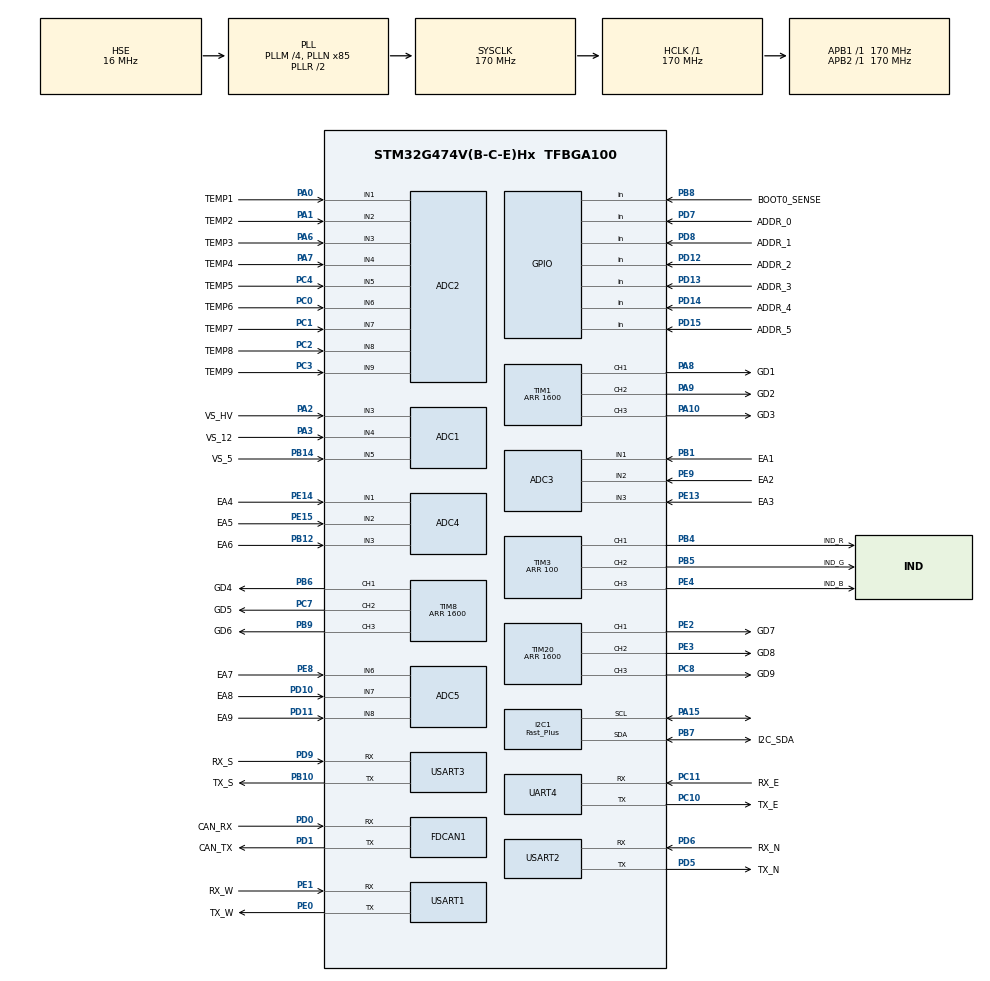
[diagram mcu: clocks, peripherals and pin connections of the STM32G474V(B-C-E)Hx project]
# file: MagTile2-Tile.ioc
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ADC1.Channel-1\#ChannelRegularConversion=ADC_CHANNEL_3
ADC1.Channel-2\#ChannelRegularConversion=ADC_CHANNEL_4
ADC1.Channel-3\#ChannelRegularConversion=ADC_CHANNEL_5
ADC1.Channel-4\#ChannelRegularConversion=ADC_CHANNEL_TEMPSENSOR_ADC1
ADC1.ClockPrescaler=ADC_CLOCK_ASYNC_DIV1
ADC1.ContinuousConvMode=ENABLE
ADC1.DMAContinuousRequests=ENABLE
ADC1.NbrOfConversion=4
ADC1.NbrOfConversionFlag=1
ADC1.OffsetNumber-1\#ChannelRegularConversion=ADC_OFFSET_NONE
ADC1.OffsetNumber-2\#ChannelRegularConversion=ADC_OFFSET_NONE
ADC1.OffsetNumber-3\#ChannelRegularConversion=ADC_OFFSET_NONE
ADC1.OffsetNumber-4\#ChannelRegularConversion=ADC_OFFSET_NONE
ADC1.OversamplingMode=ENABLE
ADC1.Rank-1\#ChannelRegularConversion=1
ADC1.Rank-2\#ChannelRegularConversion=2
ADC1.Rank-3\#ChannelRegularConversion=3
ADC1.Rank-4\#ChannelRegularConversion=4
ADC1.Ratio=ADC_OVERSAMPLING_RATIO_256
ADC1.RightBitShift=ADC_RIGHTBITSHIFT_4
ADC1.SamplingTime-1\#ChannelRegularConversion=ADC_SAMPLETIME_640CYCLES_5
ADC1.SamplingTime-2\#ChannelRegularConversion=ADC_SAMPLETIME_640CYCLES_5
ADC1.SamplingTime-3\#ChannelRegularConversion=ADC_SAMPLETIME_640CYCLES_5
ADC1.SamplingTime-4\#ChannelRegularConversion=ADC_SAMPLETIME_640CYCLES_5
ADC1.master=1
ADC2.Channel-0\#ChannelRegularConversion=ADC_CHANNEL_1
ADC2.Channel-1\#ChannelRegularConversion=ADC_CHANNEL_2
ADC2.Channel-2\#ChannelRegularConversion=ADC_CHANNEL_3
ADC2.Channel-3\#ChannelRegularConversion=ADC_CHANNEL_4
ADC2.Channel-4\#ChannelRegularConversion=ADC_CHANNEL_5
ADC2.Channel-5\#ChannelRegularConversion=ADC_CHANNEL_6
ADC2.Channel-6\#ChannelRegularConversion=ADC_CHANNEL_7
ADC2.Channel-7\#ChannelRegularConversion=ADC_CHANNEL_8
ADC2.Channel-8\#ChannelRegularConversion=ADC_CHANNEL_9
ADC2.ClockPrescaler=ADC_CLOCK_ASYNC_DIV1
ADC2.ContinuousConvMode=ENABLE
ADC2.DMAContinuousRequests=ENABLE
ADC2.NbrOfConversion=9
ADC2.NbrOfConversionFlag=1
ADC2.OffsetNumber-0\#ChannelRegularConversion=ADC_OFFSET_NONE
ADC2.OffsetNumber-1\#ChannelRegularConversion=ADC_OFFSET_NONE
ADC2.OffsetNumber-2\#ChannelRegularConversion=ADC_OFFSET_NONE
ADC2.OffsetNumber-3\#ChannelRegularConversion=ADC_OFFSET_NONE
ADC2.OffsetNumber-4\#ChannelRegularConversion=ADC_OFFSET_NONE
ADC2.OffsetNumber-5\#ChannelRegularConversion=ADC_OFFSET_NONE
ADC2.OffsetNumber-6\#ChannelRegularConversion=ADC_OFFSET_NONE
ADC2.OffsetNumber-7\#ChannelRegularConversion=ADC_OFFSET_NONE
ADC2.OffsetNumber-8\#ChannelRegularConversion=ADC_OFFSET_NONE
ADC2.OversamplingMode=ENABLE
ADC2.Rank-0\#ChannelRegularConversion=1
ADC2.Rank-1\#ChannelRegularConversion=2
ADC2.Rank-2\#ChannelRegularConversion=3
ADC2.Rank-3\#ChannelRegularConversion=4
ADC2.Rank-4\#ChannelRegularConversion=5
ADC2.Rank-5\#ChannelRegularConversion=6
ADC2.Rank-6\#ChannelRegularConversion=7
ADC2.Rank-7\#ChannelRegularConversion=8
ADC2.Rank-8\#ChannelRegularConversion=9
ADC2.Ratio=ADC_OVERSAMPLING_RATIO_16
ADC2.SamplingTime-0\#ChannelRegularConversion=ADC_SAMPLETIME_2CYCLES_5
ADC2.SamplingTime-1\#ChannelRegularConversion=ADC_SAMPLETIME_2CYCLES_5
ADC2.SamplingTime-2\#ChannelRegularConversion=ADC_SAMPLETIME_2CYCLES_5
ADC2.SamplingTime-3\#ChannelRegularConversion=ADC_SAMPLETIME_2CYCLES_5
ADC2.SamplingTime-4\#ChannelRegularConversion=ADC_SAMPLETIME_2CYCLES_5
ADC2.SamplingTime-5\#ChannelRegularConversion=ADC_SAMPLETIME_2CYCLES_5
ADC2.SamplingTime-6\#ChannelRegularConversion=ADC_SAMPLETIME_2CYCLES_5
ADC2.SamplingTime-7\#ChannelRegularConversion=ADC_SAMPLETIME_2CYCLES_5
ADC2.SamplingTime-8\#ChannelRegularConversion=ADC_SAMPLETIME_2CYCLES_5
ADC3.Channel-0\#ChannelRegularConversion=ADC_CHANNEL_1
ADC3.Channel-1\#ChannelRegularConversion=ADC_CHANNEL_2
ADC3.Channel-2\#ChannelRegularConversion=ADC_CHANNEL_3
ADC3.ClockPrescaler=ADC_CLOCK_ASYNC_DIV1
ADC3.ContinuousConvMode=ENABLE
ADC3.DMAContinuousRequests=ENABLE
ADC3.ExternalTrigConv=ADC_SOFTWARE_START
ADC3.NbrOfConversion=3
ADC3.NbrOfConversionFlag=1
ADC3.OffsetNumber-0\#ChannelRegularConversion=ADC_OFFSET_NONE
ADC3.OffsetNumber-1\#ChannelRegularConversion=ADC_OFFSET_NONE
ADC3.OffsetNumber-2\#ChannelRegularConversion=ADC_OFFSET_NONE
ADC3.Overrun=ADC_OVR_DATA_OVERWRITTEN
ADC3.OversamplingMode=ENABLE
ADC3.Rank-0\#ChannelRegularConversion=1
ADC3.Rank-1\#ChannelRegularConversion=2
ADC3.Rank-2\#ChannelRegularConversion=3
ADC3.Ratio=ADC_OVERSAMPLING_RATIO_16
ADC3.RightBitShift=ADC_RIGHTBITSHIFT_NONE
ADC3.SamplingTime-0\#ChannelRegularConversion=ADC_SAMPLETIME_47CYCLES_5
ADC3.SamplingTime-1\#ChannelRegularConversion=ADC_SAMPLETIME_47CYCLES_5
ADC3.SamplingTime-2\#ChannelRegularConversion=ADC_SAMPLETIME_47CYCLES_5
ADC3.master=1
ADC4.Channel-0\#ChannelRegularConversion=ADC_CHANNEL_1
ADC4.Channel-1\#ChannelRegularConversion=ADC_CHANNEL_2
ADC4.Channel-2\#ChannelRegularConversion=ADC_CHANNEL_3
ADC4.ClockPrescaler=ADC_CLOCK_ASYNC_DIV1
ADC4.ContinuousConvMode=ENABLE
ADC4.DMAContinuousRequests=ENABLE
ADC4.NbrOfConversion=3
ADC4.NbrOfConversionFlag=1
ADC4.OffsetNumber-0\#ChannelRegularConversion=ADC_OFFSET_NONE
ADC4.OffsetNumber-1\#ChannelRegularConversion=ADC_OFFSET_NONE
ADC4.OffsetNumber-2\#ChannelRegularConversion=ADC_OFFSET_NONE
ADC4.Overrun=ADC_OVR_DATA_OVERWRITTEN
ADC4.OversamplingMode=ENABLE
ADC4.Rank-0\#ChannelRegularConversion=1
ADC4.Rank-1\#ChannelRegularConversion=2
ADC4.Rank-2\#ChannelRegularConversion=3
ADC4.Ratio=ADC_OVERSAMPLING_RATIO_16
ADC4.RightBitShift=ADC_RIGHTBITSHIFT_NONE
ADC4.SamplingTime-0\#ChannelRegularConversion=ADC_SAMPLETIME_47CYCLES_5
ADC4.SamplingTime-1\#ChannelRegularConversion=ADC_SAMPLETIME_47CYCLES_5
ADC4.SamplingTime-2\#ChannelRegularConversion=ADC_SAMPLETIME_47CYCLES_5
ADC5.Channel-0\#ChannelRegularConversion=ADC_CHANNEL_6
ADC5.Channel-1\#ChannelRegularConversion=ADC_CHANNEL_7
ADC5.Channel-2\#ChannelRegularConversion=ADC_CHANNEL_8
ADC5.ClockPrescaler=ADC_CLOCK_ASYNC_DIV1
ADC5.ContinuousConvMode=ENABLE
ADC5.DMAContinuousRequests=ENABLE
ADC5.NbrOfConversion=3
ADC5.NbrOfConversionFlag=1
ADC5.OffsetNumber-0\#ChannelRegularConversion=ADC_OFFSET_NONE
ADC5.OffsetNumber-1\#ChannelRegularConversion=ADC_OFFSET_NONE
ADC5.OffsetNumber-2\#ChannelRegularConversion=ADC_OFFSET_NONE
ADC5.OversamplingMode=ENABLE
ADC5.Rank-0\#ChannelRegularConversion=1
ADC5.Rank-1\#ChannelRegularConversion=2
ADC5.Rank-2\#ChannelRegularConversion=3
ADC5.Ratio=ADC_OVERSAMPLING_RATIO_16
ADC5.RightBitShift=ADC_RIGHTBITSHIFT_NONE
ADC5.SamplingTime-0\#ChannelRegularConversion=ADC_SAMPLETIME_47CYCLES_5
ADC5.SamplingTime-1\#ChannelRegularConversion=ADC_SAMPLETIME_47CYCLES_5
ADC5.SamplingTime-2\#ChannelRegularConversion=ADC_SAMPLETIME_47CYCLES_5
Dma.ADC1.0.Direction=DMA_PERIPH_TO_MEMORY
Dma.ADC1.0.EventEnable=DISABLE
Dma.ADC1.0.Instance=DMA1_Channel1
Dma.ADC1.0.MemDataAlignment=DMA_MDATAALIGN_HALFWORD
Dma.ADC1.0.MemInc=DMA_MINC_ENABLE
Dma.ADC1.0.Mode=DMA_CIRCULAR
Dma.ADC1.0.PeriphDataAlignment=DMA_PDATAALIGN_HALFWORD
Dma.ADC1.0.PeriphInc=DMA_PINC_DISABLE
Dma.ADC1.0.Polarity=HAL_DMAMUX_REQ_GEN_RISING
Dma.ADC1.0.Priority=DMA_PRIORITY_MEDIUM
Dma.ADC1.0.RequestNumber=1
Dma.ADC1.0.SignalID=NONE
Dma.ADC1.0.SyncEnable=DISABLE
Dma.ADC1.0.SyncPolarity=HAL_DMAMUX_SYNC_NO_EVENT
Dma.ADC1.0.SyncRequestNumber=1
Dma.ADC1.0.SyncSignalID=NONE
Dma.ADC2.1.Direction=DMA_PERIPH_TO_MEMORY
Dma.ADC2.1.EventEnable=DISABLE
Dma.ADC2.1.Instance=DMA1_Channel2
Dma.ADC2.1.MemDataAlignment=DMA_MDATAALIGN_HALFWORD
Dma.ADC2.1.MemInc=DMA_MINC_ENABLE
Dma.ADC2.1.Mode=DMA_CIRCULAR
Dma.ADC2.1.PeriphDataAlignment=DMA_PDATAALIGN_HALFWORD
Dma.ADC2.1.PeriphInc=DMA_PINC_DISABLE
Dma.ADC2.1.Polarity=HAL_DMAMUX_REQ_GEN_RISING
Dma.ADC2.1.Priority=DMA_PRIORITY_LOW
Dma.ADC2.1.RequestNumber=1
Dma.ADC2.1.SignalID=NONE
Dma.ADC2.1.SyncEnable=DISABLE
Dma.ADC2.1.SyncPolarity=HAL_DMAMUX_SYNC_NO_EVENT
Dma.ADC2.1.SyncRequestNumber=1
Dma.ADC2.1.SyncSignalID=NONE
Dma.ADC3.2.Direction=DMA_PERIPH_TO_MEMORY
Dma.ADC3.2.EventEnable=DISABLE
Dma.ADC3.2.Instance=DMA1_Channel3
Dma.ADC3.2.MemDataAlignment=DMA_MDATAALIGN_HALFWORD
Dma.ADC3.2.MemInc=DMA_MINC_ENABLE
Dma.ADC3.2.Mode=DMA_CIRCULAR
Dma.ADC3.2.PeriphDataAlignment=DMA_PDATAALIGN_HALFWORD
Dma.ADC3.2.PeriphInc=DMA_PINC_DISABLE
Dma.ADC3.2.Polarity=HAL_DMAMUX_REQ_GEN_RISING
Dma.ADC3.2.Priority=DMA_PRIORITY_HIGH
Dma.ADC3.2.RequestNumber=1
Dma.ADC3.2.SignalID=NONE
Dma.ADC3.2.SyncEnable=DISABLE
Dma.ADC3.2.SyncPolarity=HAL_DMAMUX_SYNC_NO_EVENT
Dma.ADC3.2.SyncRequestNumber=1
Dma.ADC3.2.SyncSignalID=NONE
Dma.ADC4.3.Direction=DMA_PERIPH_TO_MEMORY
Dma.ADC4.3.EventEnable=DISABLE
Dma.ADC4.3.Instance=DMA1_Channel4
Dma.ADC4.3.MemDataAlignment=DMA_MDATAALIGN_HALFWORD
Dma.ADC4.3.MemInc=DMA_MINC_ENABLE
Dma.ADC4.3.Mode=DMA_CIRCULAR
Dma.ADC4.3.PeriphDataAlignment=DMA_PDATAALIGN_HALFWORD
Dma.ADC4.3.PeriphInc=DMA_PINC_DISABLE
Dma.ADC4.3.Polarity=HAL_DMAMUX_REQ_GEN_RISING
Dma.ADC4.3.Priority=DMA_PRIORITY_HIGH
Dma.ADC4.3.RequestNumber=1
Dma.ADC4.3.SignalID=NONE
Dma.ADC4.3.SyncEnable=DISABLE
Dma.ADC4.3.SyncPolarity=HAL_DMAMUX_SYNC_NO_EVENT
Dma.ADC4.3.SyncRequestNumber=1
Dma.ADC4.3.SyncSignalID=NONE
Dma.ADC5.4.Direction=DMA_PERIPH_TO_MEMORY
Dma.ADC5.4.EventEnable=DISABLE
Dma.ADC5.4.Instance=DMA1_Channel5
Dma.ADC5.4.MemDataAlignment=DMA_MDATAALIGN_HALFWORD
Dma.ADC5.4.MemInc=DMA_MINC_ENABLE
Dma.ADC5.4.Mode=DMA_CIRCULAR
Dma.ADC5.4.PeriphDataAlignment=DMA_PDATAALIGN_HALFWORD
Dma.ADC5.4.PeriphInc=DMA_PINC_DISABLE
Dma.ADC5.4.Polarity=HAL_DMAMUX_REQ_GEN_RISING
Dma.ADC5.4.Priority=DMA_PRIORITY_HIGH
Dma.ADC5.4.RequestNumber=1
Dma.ADC5.4.SignalID=NONE
Dma.ADC5.4.SyncEnable=DISABLE
Dma.ADC5.4.SyncPolarity=HAL_DMAMUX_SYNC_NO_EVENT
Dma.ADC5.4.SyncRequestNumber=1
Dma.ADC5.4.SyncSignalID=NONE
Dma.Request0=ADC1
Dma.Request1=ADC2
Dma.Request2=ADC3
Dma.Request3=ADC4
Dma.Request4=ADC5
FDCAN1.AutoRetransmission=ENABLE
FDCAN1.CalculateBaudRateNominal=500000
FDCAN1.CalculateTimeBitNominal=2000
FDCAN1.CalculateTimeQuantumNominal=100.0
FDCAN1.ClockDivider=FDCAN_CLOCK_DIV1
FDCAN1.DataPrescaler=6
FDCAN1.DataSyncJumpWidth=4
FDCAN1.DataTimeSeg1=11
FDCAN1.DataTimeSeg2=5
FDCAN1.FrameFormat=FDCAN_FRAME_FD_BRS
FDCAN1.NominalPrescaler=17
FDCAN1.NominalSyncJumpWidth=4
FDCAN1.NominalTimeSeg1=13
FDCAN1.NominalTimeSeg2=6
FDCAN1.TransmitPause=ENABLE
I2C1.I2C_Fall_Time=0
I2C1.I2C_Rise_Time=0
I2C1.I2C_Speed_Mode=I2C_Fast_Plus
I2C1.OwnAddress=0x01
I2C1.Timing=0x00802172
Mcu.Family=STM32G4
Mcu.Name=STM32G474V(B-C-E)Hx
Mcu.Package=TFBGA100
NVIC.DMA1_Channel1_IRQn=true\:1\:0\:true\:false\:true\:false\:true\:true
NVIC.DMA1_Channel2_IRQn=true\:3\:0\:true\:false\:true\:false\:true\:true
NVIC.DMA1_Channel3_IRQn=true\:0\:0\:true\:false\:true\:false\:true\:true
NVIC.DMA1_Channel4_IRQn=true\:0\:0\:true\:false\:true\:false\:true\:true
NVIC.DMA1_Channel5_IRQn=true\:0\:0\:true\:false\:true\:false\:true\:true
NVIC.FDCAN1_IT0_IRQn=true\:2\:0\:true\:false\:true\:true\:true\:true
NVIC.FDCAN1_IT1_IRQn=true\:2\:0\:true\:false\:true\:true\:true\:true
NVIC.PriorityGroup=NVIC_PRIORITYGROUP_4
NVIC.UART4_IRQn=true\:5\:0\:true\:false\:true\:true\:true\:true
NVIC.USART1_IRQn=true\:5\:0\:true\:false\:true\:true\:true\:true
NVIC.USART2_IRQn=true\:5\:0\:true\:false\:true\:true\:true\:true
NVIC.USART3_IRQn=true\:5\:0\:true\:false\:true\:true\:true\:true
PA0.GPIO_Label=TEMP1
PA0.Mode=IN1-Single-Ended
PA0.Signal=ADC2_IN1
PA1.GPIO_Label=TEMP2
PA1.Mode=IN2-Single-Ended
PA1.Signal=ADC2_IN2
PA10.GPIO_Label=GD3
PA10.Signal=S_TIM1_CH3
PA13.GPIO_Label=SWDIO
PA13.Mode=Trace_Asynchronous_SW
PA13.Signal=SYS_JTMS-SWDIO
PA14.GPIO_Label=SWCLK
PA14.Mode=Trace_Asynchronous_SW
PA14.Signal=SYS_JTCK-SWCLK
PA15.GPIO_Pu=GPIO_NOPULL
PA15.GPIO_Speed=GPIO_SPEED_FREQ_HIGH
PA15.Mode=I2C
PA15.Signal=I2C1_SCL
PA2.GPIO_Label=VS_HV
PA2.Mode=IN3-Single-Ended
PA2.Signal=ADC1_IN3
PA3.GPIO_Label=VS_12
PA3.Mode=IN4-Single-Ended
PA3.Signal=ADC1_IN4
PA6.GPIO_Label=TEMP3
PA6.Mode=IN3-Single-Ended
PA6.Signal=ADC2_IN3
PA7.GPIO_Label=TEMP4
PA7.Mode=IN4-Single-Ended
PA7.Signal=ADC2_IN4
PA8.GPIO_Label=GD1
PA8.Signal=S_TIM1_CH1
PA9.GPIO_Label=GD2
PA9.Signal=S_TIM1_CH2
PB1.GPIO_Label=EA1
PB1.Mode=IN1-Single-Ended
PB1.Signal=ADC3_IN1
PB10.GPIO_Label=TX_S
PB10.Mode=Asynchronous
PB10.Signal=USART3_TX
PB12.GPIO_Label=EA6
PB12.Mode=IN3-Single-Ended
PB12.Signal=ADC4_IN3
PB14.GPIO_Label=VS_5
PB14.Mode=IN5-Single-Ended
PB14.Signal=ADC1_IN5
PB3.GPIO_Label=SWO
PB3.Mode=Trace_Asynchronous_SW
PB3.Signal=SYS_JTDO-SWO
PB4.GPIO_Label=IND_R
PB4.Signal=S_TIM3_CH1
PB5.GPIO_Label=IND_G
PB5.Signal=S_TIM3_CH2
PB6.GPIO_Label=GD4
PB6.Signal=S_TIM8_CH1
PB7.GPIO_FM7=__NULL
PB7.GPIO_Label=I2C_SDA
PB7.GPIO_Pu=GPIO_NOPULL
PB7.GPIO_Speed=GPIO_SPEED_FREQ_HIGH
PB7.Mode=I2C
PB7.Signal=I2C1_SDA
PB8-BOOT0.GPIO_Label=BOOT0_SENSE
PB8-BOOT0.Signal=GPIO_Input
PB9.GPIO_Label=GD6
PB9.Signal=S_TIM8_CH3
PC0.GPIO_Label=TEMP6
PC0.Mode=IN6-Single-Ended
PC0.Signal=ADC2_IN6
PC1.GPIO_Label=TEMP7
PC1.Mode=IN7-Single-Ended
PC1.Signal=ADC2_IN7
PC10.GPIO_Label=TX_E
PC10.Mode=Asynchronous
PC10.Signal=UART4_TX
PC11.GPIO_Label=RX_E
PC11.Mode=Asynchronous
PC11.Signal=UART4_RX
PC2.GPIO_Label=TEMP8
PC2.Mode=IN8-Single-Ended
PC2.Signal=ADC2_IN8
PC3.GPIO_Label=TEMP9
PC3.Mode=IN9-Single-Ended
PC3.Signal=ADC2_IN9
PC4.GPIO_Label=TEMP5
PC4.Mode=IN5-Single-Ended
PC4.Signal=ADC2_IN5
PC7.GPIO_Label=GD5
PC7.Signal=S_TIM8_CH2
PC8.GPIO_Label=GD9
PC8.Signal=S_TIM20_CH3
PD0.GPIO_Label=CAN_RX
PD0.Mode=FDCAN_Activate
PD0.Signal=FDCAN1_RX
PD1.GPIO_Label=CAN_TX
PD1.Mode=FDCAN_Activate
PD1.Signal=FDCAN1_TX
PD10.GPIO_Label=EA8
PD10.Mode=IN7-Single-Ended
PD10.Signal=ADC5_IN7
PD11.GPIO_Label=EA9
PD11.Mode=IN8-Single-Ended
PD11.Signal=ADC5_IN8
PD12.GPIO_Label=ADDR_2
PD12.GPIO_PuPd=GPIO_PULLUP
PD12.Signal=GPIO_Input
PD13.GPIO_Label=ADDR_3
PD13.GPIO_PuPd=GPIO_PULLUP
PD13.Signal=GPIO_Input
PD14.GPIO_Label=ADDR_4
PD14.GPIO_PuPd=GPIO_PULLUP
PD14.Signal=GPIO_Input
PD15.GPIO_Label=ADDR_5
PD15.GPIO_PuPd=GPIO_PULLUP
PD15.Signal=GPIO_Input
PD5.GPIO_Label=TX_N
PD5.Mode=Asynchronous
PD5.Signal=USART2_TX
PD6.GPIO_Label=RX_N
PD6.Mode=Asynchronous
PD6.Signal=USART2_RX
PD7.GPIO_Label=ADDR_0
PD7.GPIO_PuPd=GPIO_PULLUP
PD7.Signal=GPIO_Input
PD8.GPIO_Label=ADDR_1
PD8.GPIO_PuPd=GPIO_PULLUP
PD8.Signal=GPIO_Input
PD9.GPIO_Label=RX_S
PD9.Mode=Asynchronous
PD9.Signal=USART3_RX
PE0.GPIO_Label=TX_W
PE0.Mode=Asynchronous
PE0.Signal=USART1_TX
PE1.GPIO_Label=RX_W
PE1.Mode=Asynchronous
PE1.Signal=USART1_RX
PE13.GPIO_Label=EA3
PE13.Mode=IN3-Single-Ended
PE13.Signal=ADC3_IN3
PE14.GPIO_Label=EA4
PE14.Mode=IN1-Single-Ended
PE14.Signal=ADC4_IN1
PE15.GPIO_Label=EA5
PE15.Mode=IN2-Single-Ended
PE15.Signal=ADC4_IN2
PE2.GPIO_Label=GD7
PE2.Signal=S_TIM20_CH1
PE3.GPIO_Label=GD8
PE3.Signal=S_TIM20_CH2
PE4.GPIO_Label=IND_B
PE4.Signal=S_TIM3_CH3
PE8.GPIO_Label=EA7
PE8.Mode=IN6-Single-Ended
PE8.Signal=ADC5_IN6
PE9.GPIO_Label=EA2
PE9.Mode=IN2-Single-Ended
PE9.Signal=ADC3_IN2
PF0-OSC_IN.GPIO_Label=HSE_IN
PF0-OSC_IN.Mode=HSE-External-Oscillator
PF0-OSC_IN.Signal=RCC_OSC_IN
PF1-OSC_OUT.GPIO_Label=HSE_OUT
PF1-OSC_OUT.Mode=HSE-External-Oscillator
PF1-OSC_OUT.Signal=RCC_OSC_OUT
ProjectManager.HeapSize=0x200
ProjectManager.StackSize=0x400
ProjectManager.TargetToolchain=STM32CubeIDE
RCC.ADC12CLockSelection=RCC_ADC12CLKSOURCE_PLL
RCC.ADC12Freq_Value=48571428.571428575
RCC.ADC345CLockSelection=RCC_ADC345CLKSOURCE_PLL
RCC.ADC345Freq_Value=48571428.571428575
RCC.AHBFreq_Value=170000000
RCC.APB1Freq_Value=170000000
RCC.APB1TimFreq_Value=170000000
RCC.APB2Freq_Value=170000000
RCC.APB2TimFreq_Value=170000000
RCC.CortexFreq_Value=170000000
RCC.EXTERNAL_CLOCK_VALUE=12288000
RCC.FDCANCLockSelection=RCC_FDCANCLKSOURCE_PLL
RCC.HCLKFreq_Value=170000000
RCC.HSE_VALUE=16000000
RCC.HSI48_VALUE=48000000
RCC.HSI_VALUE=16000000
RCC.LSE_VALUE=32768
RCC.PLLM=RCC_PLLM_DIV4
RCC.PLLN=85
RCC.PLLP=RCC_PLLP_DIV7
RCC.PLLSourceVirtual=RCC_PLLSOURCE_HSE
RCC.SYSCLKFreq_VALUE=170000000
RCC.SYSCLKSource=RCC_SYSCLKSOURCE_PLLCLK
RCC.USBFreq_Value=170000000
RCC.VCOOutputFreq_Value=340000000
SH.S_TIM1_CH1.0=TIM1_CH1,PWM Generation1 CH1
SH.S_TIM1_CH2.0=TIM1_CH2,PWM Generation2 CH2
SH.S_TIM1_CH3.0=TIM1_CH3,PWM Generation3 CH3
SH.S_TIM20_CH1.0=TIM20_CH1,PWM Generation1 CH1
SH.S_TIM20_CH2.0=TIM20_CH2,PWM Generation2 CH2
SH.S_TIM20_CH3.0=TIM20_CH3,PWM Generation3 CH3
SH.S_TIM3_CH1.0=TIM3_CH1,PWM Generation1 CH1
SH.S_TIM3_CH2.0=TIM3_CH2,PWM Generation2 CH2
SH.S_TIM3_CH3.0=TIM3_CH3,PWM Generation3 CH3
SH.S_TIM8_CH1.0=TIM8_CH1,PWM Generation1 CH1
SH.S_TIM8_CH2.0=TIM8_CH2,PWM Generation2 CH2
SH.S_TIM8_CH3.0=TIM8_CH3,PWM Generation3 CH3
TIM1.Channel-PWM\ Generation1\ CH1=TIM_CHANNEL_1
TIM1.Channel-PWM\ Generation2\ CH2=TIM_CHANNEL_2
TIM1.Channel-PWM\ Generation3\ CH3=TIM_CHANNEL_3
TIM1.OCFastMode_PWM-PWM\ Generation1\ CH1=TIM_OCFAST_ENABLE
TIM1.OCFastMode_PWM-PWM\ Generation2\ CH2=TIM_OCFAST_ENABLE
TIM1.OCFastMode_PWM-PWM\ Generation3\ CH3=TIM_OCFAST_ENABLE
TIM1.PeriodNoDither=1600
TIM2.Dithering=Disable
TIM2.Prescaler=16999
TIM20.Channel-PWM\ Generation1\ CH1=TIM_CHANNEL_1
TIM20.Channel-PWM\ Generation2\ CH2=TIM_CHANNEL_2
TIM20.Channel-PWM\ Generation3\ CH3=TIM_CHANNEL_3
TIM20.PeriodNoDither=1600
TIM3.Channel-PWM\ Generation1\ CH1=TIM_CHANNEL_1
TIM3.Channel-PWM\ Generation2\ CH2=TIM_CHANNEL_2
TIM3.Channel-PWM\ Generation3\ CH3=TIM_CHANNEL_3
TIM3.OCPolarity_1=TIM_OCPOLARITY_LOW
TIM3.OCPolarity_2=TIM_OCPOLARITY_LOW
TIM3.OCPolarity_3=TIM_OCPOLARITY_LOW
TIM3.PeriodNoDither=100
TIM3.PulseNoDither_1=50
TIM3.PulseNoDither_2=50
TIM6.PeriodNoDither=100
TIM6.Prescaler=168
TIM6.TIM_MasterOutputTrigger=TIM_TRGO_UPDATE
TIM8.Channel-PWM\ Generation1\ CH1=TIM_CHANNEL_1
TIM8.Channel-PWM\ Generation2\ CH2=TIM_CHANNEL_2
TIM8.Channel-PWM\ Generation3\ CH3=TIM_CHANNEL_3
TIM8.PeriodNoDither=1600
USART1.VirtualMode-Asynchronous=VM_ASYNC
USART2.VirtualMode-Asynchronous=VM_ASYNC
USART3.VirtualMode-Asynchronous=VM_ASYNC
VP_ADC1_TempSens_Input.Mode=IN-TempSens
VP_SYS_VS_DBSignals.Mode=DisableDeadBatterySignals
VP_TIM1_VS_ClockSourceINT.Mode=Internal
VP_TIM20_VS_ClockSourceINT.Mode=Internal
VP_TIM2_VS_ClockSourceINT.Mode=Internal
VP_TIM3_VS_ClockSourceINT.Mode=Internal
VP_TIM6_VS_ClockSourceINT.Mode=Enable_Timer
VP_TIM8_VS_ClockSourceINT.Mode=Internal
board=custom

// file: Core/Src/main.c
/* USER CODE BEGIN Header */
/**
 ******************************************************************************
 * @file           : main.c
 * @brief          : Main program body
 ******************************************************************************
 * @attention
 *
 * Copyright (c) 2025 STMicroelectronics.
 * All rights reserved.
 *
 * This software is licensed under terms that can be found in the LICENSE file
 * in the root directory of this software component.
 * If no LICENSE file comes with this software, it is provided AS-IS.
 *
 ******************************************************************************
 */
/* USER CODE END Header */
#include "main.h"

/* USER CODE BEGIN Includes */

#include "i2c_slave.h"
#include "can.h"
#include "adc.h"
#include "telemetry.h"
#include "graph_uart.h"
#include "safety_config.h"

/* USER CODE END Includes */

/* USER CODE BEGIN PD */

#define I2C_BUFFER_SIZE 2
#define CAN_BLINK_FREQ 200 // ms
#define CAN_BLINK_TIME 100 // ms
#define ID_BLINK_FREQ 300 // ms
#define ID_BLINK_TIME 100 // ms

/* USER CODE END PD */

ADC_HandleTypeDef hadc1;
ADC_HandleTypeDef hadc2;
ADC_HandleTypeDef hadc3;
ADC_HandleTypeDef hadc4;
ADC_HandleTypeDef hadc5;
DMA_HandleTypeDef hdma_adc1;
DMA_HandleTypeDef hdma_adc2;
DMA_HandleTypeDef hdma_adc3;
DMA_HandleTypeDef hdma_adc4;
DMA_HandleTypeDef hdma_adc5;

FDCAN_HandleTypeDef hfdcan1;

I2C_HandleTypeDef hi2c1;

TIM_HandleTypeDef htim1;
TIM_HandleTypeDef htim2;
TIM_HandleTypeDef htim3;
TIM_HandleTypeDef htim6;
TIM_HandleTypeDef htim8;
TIM_HandleTypeDef htim20;

UART_HandleTypeDef huart4;
UART_HandleTypeDef huart1;
UART_HandleTypeDef huart2;
UART_HandleTypeDef huart3;

/* USER CODE BEGIN PV */

uint16_t build_number = 24;

unsigned int hardware_tick = 0; // hardware tick counter

// global variables for all digital inputs
uint8_t BOOT0_SENSE;

uint8_t my_address = 0x00;

MT2_Slave_Status slave_status;
MT2_Slave_Faults slave_faults;
MT2_Global_State global_state;
MT2_Slave_Settings slave_settings;

uint8_t adj_west_addr;
uint8_t adj_north_addr;
uint8_t adj_east_addr;
uint8_t adj_south_addr;

volatile float coil_current_1 = 0;

// PWM outputs
uint16_t coil_pwm_ccr_1 = 0;

FDCAN_RxHeaderTypeDef rxHeader;
uint8_t rxData[8];
uint8_t i2c_blink = 0;
uint8_t can_blink = 0;

int32_t can_latency = 0; // time since last CAN message received
uint8_t can_timeout = 0; // flag for CAN timeout

// I2C RX buffer
uint8_t i2cRxBuffer[I2C_BUFFER_SIZE];
uint8_t i2cRxIndex = 0;
uint8_t i2cDataReady = 0;

uint32_t main_loop_counter = 0; // main loop counter for debugging
volatile uint32_t adc3_loop_counter = 0; // adc1 loop counter for debugging
volatile uint32_t adc4_loop_counter = 0; // adc2 loop counter for debugging
volatile uint32_t adc5_loop_counter = 0; // adc3 loop counter for debugging
uint32_t main_loop_freq = 0; // main loop frequency in Hz
uint32_t adc3_loop_freq = 0; // adc1 loop frequency in Hz
uint32_t adc4_loop_freq = 0; // adc2 loop frequency in Hz
uint32_t adc5_loop_freq = 0; // adc3 loop frequency in Hz

/* USER CODE END PV */

void SystemClock_Config(void);
static void MX_GPIO_Init(void);
static void MX_DMA_Init(void);
static void MX_ADC1_Init(void);
static void MX_ADC2_Init(void);
static void MX_ADC3_Init(void);
static void MX_ADC4_Init(void);
static void MX_ADC5_Init(void);
static void MX_TIM1_Init(void);
static void MX_TIM8_Init(void);
static void MX_TIM20_Init(void);
static void MX_FDCAN1_Init(void);
static void MX_I2C1_Init(void);
static void MX_TIM3_Init(void);
static void MX_UART4_Init(void);
static void MX_USART1_UART_Init(void);
static void MX_USART2_UART_Init(void);
static void MX_USART3_UART_Init(void);
static void MX_TIM6_Init(void);
static void MX_TIM2_Init(void);

/* USER CODE BEGIN 0 */

#define _set_rgb(r, g, b) \
	__HAL_TIM_SET_COMPARE(&htim3, TIM_CHANNEL_1, (g)); \
	__HAL_TIM_SET_COMPARE(&htim3, TIM_CHANNEL_2, (r)); \
	__HAL_TIM_SET_COMPARE(&htim3, TIM_CHANNEL_3, (b)); \

#define LED_BRIGHTNESS_DIVIDE 2
void set_rgb(uint8_t r, uint8_t g, uint8_t b) {
	_set_rgb(r/LED_BRIGHTNESS_DIVIDE, g/LED_BRIGHTNESS_DIVIDE, b/LED_BRIGHTNESS_DIVIDE);
}

/* USER CODE END 0 */

int main(void)
{

  /* MCU Configuration--------------------------------------------------------*/

  /* Reset of all peripherals, Initializes the Flash interface and the Systick. */
  HAL_Init();

  /* Configure the system clock */
  SystemClock_Config();

  /* Initialize all configured peripherals */
  MX_GPIO_Init();
  MX_DMA_Init();
  MX_ADC1_Init();
  MX_ADC2_Init();
  MX_ADC3_Init();
  MX_ADC4_Init();
  MX_ADC5_Init();
  MX_TIM1_Init();
  MX_TIM8_Init();
  MX_TIM20_Init();
  MX_FDCAN1_Init();
  MX_I2C1_Init();
  MX_TIM3_Init();
  MX_UART4_Init();
  MX_USART1_UART_Init();
  MX_USART2_UART_Init();
  MX_USART3_UART_Init();
  MX_TIM6_Init();
  MX_TIM2_Init();
  /* USER CODE BEGIN 2 */

  // start hardware tick timer
  HAL_TIM_Base_Start(&htim2);

	// 1: green; 2: red; 3: blue
	// set LED to red
//	set_rgb(100, 0, 0);

	// turn on LED pwm
	HAL_TIM_PWM_Start(&htim3, TIM_CHANNEL_1);
	HAL_TIM_PWM_Start(&htim3, TIM_CHANNEL_2);
	HAL_TIM_PWM_Start(&htim3, TIM_CHANNEL_3);

//	HAL_Delay(1000);

	uint8_t new_addr_switches = 0;
	new_addr_switches |= !HAL_GPIO_ReadPin(ADDR_0_GPIO_Port, ADDR_0_Pin) << 5;
	new_addr_switches |= !HAL_GPIO_ReadPin(ADDR_1_GPIO_Port, ADDR_1_Pin) << 4;
	new_addr_switches |= !HAL_GPIO_ReadPin(ADDR_2_GPIO_Port, ADDR_2_Pin) << 3;
	new_addr_switches |= !HAL_GPIO_ReadPin(ADDR_3_GPIO_Port, ADDR_3_Pin) << 2;
	new_addr_switches |= !HAL_GPIO_ReadPin(ADDR_4_GPIO_Port, ADDR_4_Pin) << 1;
	new_addr_switches |= !HAL_GPIO_ReadPin(ADDR_5_GPIO_Port, ADDR_5_Pin) << 0;
	my_address = new_addr_switches + 1;
	hi2c1.Init.OwnAddress1 = my_address << 1;
	HAL_I2C_Init(&hi2c1);

	// start the ADCs
//	HAL_ADC_Start_IT(&hadc3);
	ADC_Init(&hadc1, &hadc2, &hadc3, &hadc4, &hadc5);

	// start the timer
	HAL_TIM_Base_Start(&htim6);

	// start the gate drive PWM timers
	HAL_TIM_PWM_Start(&htim1, TIM_CHANNEL_1);
	HAL_TIM_PWM_Start(&htim1, TIM_CHANNEL_2);
	HAL_TIM_PWM_Start(&htim1, TIM_CHANNEL_3);
	HAL_TIM_PWM_Start(&htim8, TIM_CHANNEL_1);
	HAL_TIM_PWM_Start(&htim8, TIM_CHANNEL_2);
	HAL_TIM_PWM_Start(&htim8, TIM_CHANNEL_3);
	HAL_TIM_PWM_Start(&htim20, TIM_CHANNEL_1);
	HAL_TIM_PWM_Start(&htim20, TIM_CHANNEL_2);
	HAL_TIM_PWM_Start(&htim20, TIM_CHANNEL_3);

	// start CAN
	CAN_Init(&hfdcan1);

	slave_status.flags.alive = 1;

	Telemetry_Init();

	I2C_Slave_Init(&hi2c1);

	GraphUART_Init(&huart2, &huart4, &huart3, &huart1);

	CoreDebug->DEMCR |= CoreDebug_DEMCR_TRCENA_Msk; // Enable trace
	ITM->LAR  = 0xC5ACCE55;                         // Unlock ITM
	ITM->TCR  = ITM_TCR_ITMENA_Msk |                // Enable ITM
				ITM_TCR_SYNCENA_Msk |               // Enable sync packets (optional)
				ITM_TCR_TSENA_Msk;                  // Enable timestamping (optional)
	ITM->TER  = 0xFFFFFFFF;                         // Enable all stimulus ports

	// set LED to yellow
//	set_rgb(100, 100, 0);

	uint32_t graph_uart_start = HAL_GetTick();

	uint32_t can_blink_start = HAL_GetTick();
	uint32_t id_blink_start = HAL_GetTick();
	uint32_t loop_diagnostics_start = HAL_GetTick();

	uint8_t led_off = 0; // flag to indicate if led is off
	uint8_t led_id_mode = 0; // flag to indicate if in id mode

  /* USER CODE END 2 */

  /* Infinite loop */
	while (1) {

    /* USER CODE BEGIN 3 */

		// set hardware tick
		hardware_tick = __HAL_TIM_GET_COUNTER(&htim2) / 10;

		// read digital inputs
		BOOT0_SENSE = HAL_GPIO_ReadPin(BOOT0_SENSE_GPIO_Port, BOOT0_SENSE_Pin);

		// set timer output
		__HAL_TIM_SET_COMPARE(&htim1, TIM_CHANNEL_1, coil_pwm_ccr[0]);
		__HAL_TIM_SET_COMPARE(&htim1, TIM_CHANNEL_2, coil_pwm_ccr[1]);
		__HAL_TIM_SET_COMPARE(&htim1, TIM_CHANNEL_3, coil_pwm_ccr[2]);
		__HAL_TIM_SET_COMPARE(&htim8, TIM_CHANNEL_1, coil_pwm_ccr[3]);
		__HAL_TIM_SET_COMPARE(&htim8, TIM_CHANNEL_2, coil_pwm_ccr[4]);
		__HAL_TIM_SET_COMPARE(&htim8, TIM_CHANNEL_3, coil_pwm_ccr[5]);
		__HAL_TIM_SET_COMPARE(&htim20, TIM_CHANNEL_1, coil_pwm_ccr[6]);
		__HAL_TIM_SET_COMPARE(&htim20, TIM_CHANNEL_2, coil_pwm_ccr[7]);
		__HAL_TIM_SET_COMPARE(&htim20, TIM_CHANNEL_3, coil_pwm_ccr[8]);

		// STATE MACHINE START

		// check global state parameters
		if (global_state.flags.global_fault_clear || slave_settings.flags.local_fault_clear) {
			slave_status.flags.shutdown_from_fault = 0;
		}

		// check if any coils are on
		for (int i = 0; i < 9; i++) {
			if (coil_setpoint[i] > 0) {
				slave_status.flags.coils_nonzero = 1;
				break;
			} else {
				slave_status.flags.coils_nonzero = 0;
			}
		}

		// CAN-related state
		if (!slave_status.flags.arm_active && !slave_status.flags.shutdown_from_fault) {
			slave_faults.flags.communication_fault = 0;
		}
		can_latency = HAL_GetTick() - can_last_heard_from_master;
		if (can_latency > CAN_TIMEOUT) {
			can_timeout = 1;
			global_state.flags.global_led_disable = 0;
			slave_faults.flags.communication_fault = 1;
		}
		else {
			can_timeout = 0;
		}

		// check for faults and disarm
		if (slave_status.flags.arm_active && slave_faults.byte) {
			slave_status.flags.shutdown_from_fault = 1;
			slave_status.flags.arm_active = 0;
		}

		if (slave_faults.byte)
			slave_status.flags.arm_ready = 0;
		else
			slave_status.flags.arm_ready = 1;

		// now finally if there are no faults and the global arm request is on
		if (global_state.flags.global_arm && !slave_faults.byte) {
			slave_status.flags.arm_active = 1;
		} else {
			slave_status.flags.arm_active = 0;
		}

		// POST STATE MACHINE

	    // turn can led off for CAN_BLINK_TIME every CAN_BLINK_FREQ ms
		if (HAL_GetTick() - can_blink_start > CAN_BLINK_FREQ) {
			can_blink_start = HAL_GetTick();
			if (can_timeout) led_off = 1;
		}
		if (HAL_GetTick() - can_blink_start > CAN_BLINK_TIME) {
			led_off = 0;
		}

		if (HAL_GetTick() - id_blink_start > ID_BLINK_FREQ) {
			id_blink_start = HAL_GetTick();
			if (slave_settings.flags.identify) led_id_mode = 1;
		}
		if (HAL_GetTick() - id_blink_start > ID_BLINK_TIME) {
			led_id_mode = 0;
		}

		if (global_state.flags.global_led_disable || (HAL_GetTick() < 500)) {
			set_rgb(0, 0, 0);
		} else {
			if (led_id_mode) { // White: ID mode
				_set_rgb(90, 100, 90);
			} else if (led_off) { // Off: Communication fault
				set_rgb(0, 0, 0);
			} else if (slave_status.flags.coils_nonzero) { // Blue: coils are on
				set_rgb(0, 0, 100);
			} else if (slave_status.flags.arm_active) { // Green: armed
				set_rgb(0, 100, 0);
			} else if (slave_faults.byte) { // Red: fault
				set_rgb(100, 0, 0);
			} else { // Yellow: idle
				set_rgb(100, 100, 0);
			}
		}

		// Handle CAN failure
		CAN_KeepAlive();

		Telemetry_Loop();

		if (HAL_GetTick() - graph_uart_start > 100) {
			graph_uart_start = HAL_GetTick();
			GraphUART_PeriodicUpdate();
		}

		main_loop_counter++;
		if (HAL_GetTick() - loop_diagnostics_start > 100) {
			loop_diagnostics_start = HAL_GetTick();
			main_loop_freq = main_loop_counter;
			main_loop_counter = 0;
			adc3_loop_freq = adc3_loop_counter;
			adc3_loop_counter = 0;
			adc4_loop_freq = adc4_loop_counter;
			adc4_loop_counter = 0;
			adc5_loop_freq = adc5_loop_counter;
			adc5_loop_counter = 0;
		}

	}
  /* USER CODE END 3 */
}

void SystemClock_Config(void)
{
  RCC_OscInitTypeDef RCC_OscInitStruct = {0};
  RCC_ClkInitTypeDef RCC_ClkInitStruct = {0};

  /** Configure the main internal regulator output voltage
  */
  HAL_PWREx_ControlVoltageScaling(PWR_REGULATOR_VOLTAGE_SCALE1_BOOST);

  /** Initializes the RCC Oscillators according to the specified parameters
  * in the RCC_OscInitTypeDef structure.
  */
  RCC_OscInitStruct.OscillatorType = RCC_OSCILLATORTYPE_HSE;
  RCC_OscInitStruct.HSEState = RCC_HSE_ON;
  RCC_OscInitStruct.PLL.PLLState = RCC_PLL_ON;
  RCC_OscInitStruct.PLL.PLLSource = RCC_PLLSOURCE_HSE;
  RCC_OscInitStruct.PLL.PLLM = RCC_PLLM_DIV4;
  RCC_OscInitStruct.PLL.PLLN = 85;
  RCC_OscInitStruct.PLL.PLLP = RCC_PLLP_DIV7;
  RCC_OscInitStruct.PLL.PLLQ = RCC_PLLQ_DIV2;
  RCC_OscInitStruct.PLL.PLLR = RCC_PLLR_DIV2;
  if (HAL_RCC_OscConfig(&RCC_OscInitStruct) != HAL_OK)
  {
    Error_Handler();
  }

  /** Initializes the CPU, AHB and APB buses clocks
  */
  RCC_ClkInitStruct.ClockType = RCC_CLOCKTYPE_HCLK|RCC_CLOCKTYPE_SYSCLK
                              |RCC_CLOCKTYPE_PCLK1|RCC_CLOCKTYPE_PCLK2;
  RCC_ClkInitStruct.SYSCLKSource = RCC_SYSCLKSOURCE_PLLCLK;
  RCC_ClkInitStruct.AHBCLKDivider = RCC_SYSCLK_DIV1;
  RCC_ClkInitStruct.APB1CLKDivider = RCC_HCLK_DIV1;
  RCC_ClkInitStruct.APB2CLKDivider = RCC_HCLK_DIV1;

  if (HAL_RCC_ClockConfig(&RCC_ClkInitStruct, FLASH_LATENCY_4) != HAL_OK)
  {
    Error_Handler();
  }
}

static void MX_ADC1_Init(void)
{

  ADC_MultiModeTypeDef multimode = {0};
  ADC_ChannelConfTypeDef sConfig = {0};

  /** Common config
  */
  hadc1.Instance = ADC1;
  hadc1.Init.ClockPrescaler = ADC_CLOCK_ASYNC_DIV1;
  hadc1.Init.Resolution = ADC_RESOLUTION_12B;
  hadc1.Init.DataAlign = ADC_DATAALIGN_RIGHT;
  hadc1.Init.GainCompensation = 0;
  hadc1.Init.ScanConvMode = ADC_SCAN_ENABLE;
  hadc1.Init.EOCSelection = ADC_EOC_SINGLE_CONV;
  hadc1.Init.LowPowerAutoWait = DISABLE;
  hadc1.Init.ContinuousConvMode = ENABLE;
  hadc1.Init.NbrOfConversion = 4;
  hadc1.Init.DiscontinuousConvMode = DISABLE;
  hadc1.Init.ExternalTrigConv = ADC_SOFTWARE_START;
  hadc1.Init.ExternalTrigConvEdge = ADC_EXTERNALTRIGCONVEDGE_NONE;
  hadc1.Init.DMAContinuousRequests = ENABLE;
  hadc1.Init.Overrun = ADC_OVR_DATA_PRESERVED;
  hadc1.Init.OversamplingMode = ENABLE;
  hadc1.Init.Oversampling.Ratio = ADC_OVERSAMPLING_RATIO_256;
  hadc1.Init.Oversampling.RightBitShift = ADC_RIGHTBITSHIFT_4;
  hadc1.Init.Oversampling.TriggeredMode = ADC_TRIGGEREDMODE_SINGLE_TRIGGER;
  hadc1.Init.Oversampling.OversamplingStopReset = ADC_REGOVERSAMPLING_CONTINUED_MODE;
  if (HAL_ADC_Init(&hadc1) != HAL_OK)
  {
    Error_Handler();
  }

  /** Configure the ADC multi-mode
  */
  multimode.Mode = ADC_MODE_INDEPENDENT;
  if (HAL_ADCEx_MultiModeConfigChannel(&hadc1, &multimode) != HAL_OK)
  {
    Error_Handler();
  }

  /** Configure Regular Channel
  */
  sConfig.Channel = ADC_CHANNEL_3;
  sConfig.Rank = ADC_REGULAR_RANK_1;
  sConfig.SamplingTime = ADC_SAMPLETIME_640CYCLES_5;
  sConfig.SingleDiff = ADC_SINGLE_ENDED;
  sConfig.OffsetNumber = ADC_OFFSET_NONE;
  sConfig.Offset = 0;
  if (HAL_ADC_ConfigChannel(&hadc1, &sConfig) != HAL_OK)
  {
    Error_Handler();
  }

  /** Configure Regular Channel
  */
  sConfig.Channel = ADC_CHANNEL_4;
  sConfig.Rank = ADC_REGULAR_RANK_2;
  if (HAL_ADC_ConfigChannel(&hadc1, &sConfig) != HAL_OK)
  {
    Error_Handler();
  }

  /** Configure Regular Channel
  */
  sConfig.Channel = ADC_CHANNEL_5;
  sConfig.Rank = ADC_REGULAR_RANK_3;
  if (HAL_ADC_ConfigChannel(&hadc1, &sConfig) != HAL_OK)
  {
    Error_Handler();
  }

  /** Configure Regular Channel
  */
  sConfig.Channel = ADC_CHANNEL_TEMPSENSOR_ADC1;
  sConfig.Rank = ADC_REGULAR_RANK_4;
  if (HAL_ADC_ConfigChannel(&hadc1, &sConfig) != HAL_OK)
  {
    Error_Handler();
  }

}

static void MX_ADC2_Init(void)
{

  ADC_ChannelConfTypeDef sConfig = {0};

  /** Common config
  */
  hadc2.Instance = ADC2;
  hadc2.Init.ClockPrescaler = ADC_CLOCK_ASYNC_DIV1;
  hadc2.Init.Resolution = ADC_RESOLUTION_12B;
  hadc2.Init.DataAlign = ADC_DATAALIGN_RIGHT;
  hadc2.Init.GainCompensation = 0;
  hadc2.Init.ScanConvMode = ADC_SCAN_ENABLE;
  hadc2.Init.EOCSelection = ADC_EOC_SINGLE_CONV;
  hadc2.Init.LowPowerAutoWait = DISABLE;
  hadc2.Init.ContinuousConvMode = ENABLE;
  hadc2.Init.NbrOfConversion = 9;
  hadc2.Init.DiscontinuousConvMode = DISABLE;
  hadc2.Init.ExternalTrigConv = ADC_SOFTWARE_START;
  hadc2.Init.ExternalTrigConvEdge = ADC_EXTERNALTRIGCONVEDGE_NONE;
  hadc2.Init.DMAContinuousRequests = ENABLE;
  hadc2.Init.Overrun = ADC_OVR_DATA_PRESERVED;
  hadc2.Init.OversamplingMode = ENABLE;
  hadc2.Init.Oversampling.Ratio = ADC_OVERSAMPLING_RATIO_16;
  hadc2.Init.Oversampling.RightBitShift = ADC_RIGHTBITSHIFT_NONE;
  hadc2.Init.Oversampling.TriggeredMode = ADC_TRIGGEREDMODE_SINGLE_TRIGGER;
  hadc2.Init.Oversampling.OversamplingStopReset = ADC_REGOVERSAMPLING_CONTINUED_MODE;
  if (HAL_ADC_Init(&hadc2) != HAL_OK)
  {
    Error_Handler();
  }

  /** Configure Regular Channel
  */
  sConfig.Channel = ADC_CHANNEL_1;
  sConfig.Rank = ADC_REGULAR_RANK_1;
  sConfig.SamplingTime = ADC_SAMPLETIME_2CYCLES_5;
  sConfig.SingleDiff = ADC_SINGLE_ENDED;
  sConfig.OffsetNumber = ADC_OFFSET_NONE;
  sConfig.Offset = 0;
  if (HAL_ADC_ConfigChannel(&hadc2, &sConfig) != HAL_OK)
  {
    Error_Handler();
  }

  /** Configure Regular Channel
  */
  sConfig.Channel = ADC_CHANNEL_2;
  sConfig.Rank = ADC_REGULAR_RANK_2;
  if (HAL_ADC_ConfigChannel(&hadc2, &sConfig) != HAL_OK)
  {
    Error_Handler();
  }

  /** Configure Regular Channel
  */
  sConfig.Channel = ADC_CHANNEL_3;
  sConfig.Rank = ADC_REGULAR_RANK_3;
  if (HAL_ADC_ConfigChannel(&hadc2, &sConfig) != HAL_OK)
  {
    Error_Handler();
  }

  /** Configure Regular Channel
  */
  sConfig.Channel = ADC_CHANNEL_4;
  sConfig.Rank = ADC_REGULAR_RANK_4;
  if (HAL_ADC_ConfigChannel(&hadc2, &sConfig) != HAL_OK)
  {
    Error_Handler();
  }

  /** Configure Regular Channel
  */
  sConfig.Channel = ADC_CHANNEL_5;
  sConfig.Rank = ADC_REGULAR_RANK_5;
  if (HAL_ADC_ConfigChannel(&hadc2, &sConfig) != HAL_OK)
  {
    Error_Handler();
  }

  /** Configure Regular Channel
  */
  sConfig.Channel = ADC_CHANNEL_6;
  sConfig.Rank = ADC_REGULAR_RANK_6;
  if (HAL_ADC_ConfigChannel(&hadc2, &sConfig) != HAL_OK)
  {
    Error_Handler();
  }

  /** Configure Regular Channel
  */
  sConfig.Channel = ADC_CHANNEL_7;
  sConfig.Rank = ADC_REGULAR_RANK_7;
  if (HAL_ADC_ConfigChannel(&hadc2, &sConfig) != HAL_OK)
  {
    Error_Handler();
  }

  /** Configure Regular Channel
  */
  sConfig.Channel = ADC_CHANNEL_8;
  sConfig.Rank = ADC_REGULAR_RANK_8;
  if (HAL_ADC_ConfigChannel(&hadc2, &sConfig) != HAL_OK)
  {
    Error_Handler();
  }

  /** Configure Regular Channel
  */
  sConfig.Channel = ADC_CHANNEL_9;
  sConfig.Rank = ADC_REGULAR_RANK_9;
  if (HAL_ADC_ConfigChannel(&hadc2, &sConfig) != HAL_OK)
  {
    Error_Handler();
  }

}

static void MX_ADC3_Init(void)
{

  ADC_MultiModeTypeDef multimode = {0};
  ADC_ChannelConfTypeDef sConfig = {0};

  /** Common config
  */
  hadc3.Instance = ADC3;
  hadc3.Init.ClockPrescaler = ADC_CLOCK_ASYNC_DIV1;
  hadc3.Init.Resolution = ADC_RESOLUTION_12B;
  hadc3.Init.DataAlign = ADC_DATAALIGN_RIGHT;
  hadc3.Init.GainCompensation = 0;
  hadc3.Init.ScanConvMode = ADC_SCAN_ENABLE;
  hadc3.Init.EOCSelection = ADC_EOC_SINGLE_CONV;
  hadc3.Init.LowPowerAutoWait = DISABLE;
  hadc3.Init.ContinuousConvMode = ENABLE;
  hadc3.Init.NbrOfConversion = 3;
  hadc3.Init.DiscontinuousConvMode = DISABLE;
  hadc3.Init.ExternalTrigConv = ADC_SOFTWARE_START;
  hadc3.Init.ExternalTrigConvEdge = ADC_EXTERNALTRIGCONVEDGE_NONE;
  hadc3.Init.DMAContinuousRequests = ENABLE;
  hadc3.Init.Overrun = ADC_OVR_DATA_OVERWRITTEN;
  hadc3.Init.OversamplingMode = ENABLE;
  hadc3.Init.Oversampling.Ratio = ADC_OVERSAMPLING_RATIO_16;
  hadc3.Init.Oversampling.RightBitShift = ADC_RIGHTBITSHIFT_NONE;
  hadc3.Init.Oversampling.TriggeredMode = ADC_TRIGGEREDMODE_SINGLE_TRIGGER;
  hadc3.Init.Oversampling.OversamplingStopReset = ADC_REGOVERSAMPLING_CONTINUED_MODE;
  if (HAL_ADC_Init(&hadc3) != HAL_OK)
  {
    Error_Handler();
  }

  /** Configure the ADC multi-mode
  */
  multimode.Mode = ADC_MODE_INDEPENDENT;
  if (HAL_ADCEx_MultiModeConfigChannel(&hadc3, &multimode) != HAL_OK)
  {
    Error_Handler();
  }

  /** Configure Regular Channel
  */
  sConfig.Channel = ADC_CHANNEL_1;
  sConfig.Rank = ADC_REGULAR_RANK_1;
  sConfig.SamplingTime = ADC_SAMPLETIME_47CYCLES_5;
  sConfig.SingleDiff = ADC_SINGLE_ENDED;
  sConfig.OffsetNumber = ADC_OFFSET_NONE;
  sConfig.Offset = 0;
  if (HAL_ADC_ConfigChannel(&hadc3, &sConfig) != HAL_OK)
  {
    Error_Handler();
  }

  /** Configure Regular Channel
  */
  sConfig.Channel = ADC_CHANNEL_2;
  sConfig.Rank = ADC_REGULAR_RANK_2;
  if (HAL_ADC_ConfigChannel(&hadc3, &sConfig) != HAL_OK)
  {
    Error_Handler();
  }

  /** Configure Regular Channel
  */
  sConfig.Channel = ADC_CHANNEL_3;
  sConfig.Rank = ADC_REGULAR_RANK_3;
  if (HAL_ADC_ConfigChannel(&hadc3, &sConfig) != HAL_OK)
  {
    Error_Handler();
  }

}

static void MX_ADC4_Init(void)
{

  ADC_ChannelConfTypeDef sConfig = {0};

  /** Common config
  */
  hadc4.Instance = ADC4;
  hadc4.Init.ClockPrescaler = ADC_CLOCK_ASYNC_DIV1;
  hadc4.Init.Resolution = ADC_RESOLUTION_12B;
  hadc4.Init.DataAlign = ADC_DATAALIGN_RIGHT;
  hadc4.Init.GainCompensation = 0;
  hadc4.Init.ScanConvMode = ADC_SCAN_ENABLE;
  hadc4.Init.EOCSelection = ADC_EOC_SINGLE_CONV;
  hadc4.Init.LowPowerAutoWait = DISABLE;
  hadc4.Init.ContinuousConvMode = ENABLE;
  hadc4.Init.NbrOfConversion = 3;
  hadc4.Init.DiscontinuousConvMode = DISABLE;
  hadc4.Init.ExternalTrigConv = ADC_SOFTWARE_START;
  hadc4.Init.ExternalTrigConvEdge = ADC_EXTERNALTRIGCONVEDGE_NONE;
  hadc4.Init.DMAContinuousRequests = ENABLE;
  hadc4.Init.Overrun = ADC_OVR_DATA_OVERWRITTEN;
  hadc4.Init.OversamplingMode = ENABLE;
  hadc4.Init.Oversampling.Ratio = ADC_OVERSAMPLING_RATIO_16;
  hadc4.Init.Oversampling.RightBitShift = ADC_RIGHTBITSHIFT_NONE;
  hadc4.Init.Oversampling.TriggeredMode = ADC_TRIGGEREDMODE_SINGLE_TRIGGER;
  hadc4.Init.Oversampling.OversamplingStopReset = ADC_REGOVERSAMPLING_CONTINUED_MODE;
  if (HAL_ADC_Init(&hadc4) != HAL_OK)
  {
    Error_Handler();
  }

  /** Configure Regular Channel
  */
  sConfig.Channel = ADC_CHANNEL_1;
  sConfig.Rank = ADC_REGULAR_RANK_1;
  sConfig.SamplingTime = ADC_SAMPLETIME_47CYCLES_5;
  sConfig.SingleDiff = ADC_SINGLE_ENDED;
  sConfig.OffsetNumber = ADC_OFFSET_NONE;
  sConfig.Offset = 0;
  if (HAL_ADC_ConfigChannel(&hadc4, &sConfig) != HAL_OK)
  {
    Error_Handler();
  }

  /** Configure Regular Channel
  */
  sConfig.Channel = ADC_CHANNEL_2;
  sConfig.Rank = ADC_REGULAR_RANK_2;
  if (HAL_ADC_ConfigChannel(&hadc4, &sConfig) != HAL_OK)
  {
    Error_Handler();
  }

  /** Configure Regular Channel
  */
  sConfig.Channel = ADC_CHANNEL_3;
  sConfig.Rank = ADC_REGULAR_RANK_3;
  if (HAL_ADC_ConfigChannel(&hadc4, &sConfig) != HAL_OK)
  {
    Error_Handler();
  }

}

static void MX_ADC5_Init(void)
{

  ADC_ChannelConfTypeDef sConfig = {0};

  /** Common config
  */
  hadc5.Instance = ADC5;
  hadc5.Init.ClockPrescaler = ADC_CLOCK_ASYNC_DIV1;
  hadc5.Init.Resolution = ADC_RESOLUTION_12B;
  hadc5.Init.DataAlign = ADC_DATAALIGN_RIGHT;
  hadc5.Init.GainCompensation = 0;
  hadc5.Init.ScanConvMode = ADC_SCAN_ENABLE;
  hadc5.Init.EOCSelection = ADC_EOC_SINGLE_CONV;
  hadc5.Init.LowPowerAutoWait = DISABLE;
  hadc5.Init.ContinuousConvMode = ENABLE;
  hadc5.Init.NbrOfConversion = 3;
  hadc5.Init.DiscontinuousConvMode = DISABLE;
  hadc5.Init.ExternalTrigConv = ADC_SOFTWARE_START;
  hadc5.Init.ExternalTrigConvEdge = ADC_EXTERNALTRIGCONVEDGE_NONE;
  hadc5.Init.DMAContinuousRequests = ENABLE;
  hadc5.Init.Overrun = ADC_OVR_DATA_PRESERVED;
  hadc5.Init.OversamplingMode = ENABLE;
  hadc5.Init.Oversampling.Ratio = ADC_OVERSAMPLING_RATIO_16;
  hadc5.Init.Oversampling.RightBitShift = ADC_RIGHTBITSHIFT_NONE;
  hadc5.Init.Oversampling.TriggeredMode = ADC_TRIGGEREDMODE_SINGLE_TRIGGER;
  hadc5.Init.Oversampling.OversamplingStopReset = ADC_REGOVERSAMPLING_CONTINUED_MODE;
  if (HAL_ADC_Init(&hadc5) != HAL_OK)
  {
    Error_Handler();
  }

  /** Configure Regular Channel
  */
  sConfig.Channel = ADC_CHANNEL_6;
  sConfig.Rank = ADC_REGULAR_RANK_1;
  sConfig.SamplingTime = ADC_SAMPLETIME_47CYCLES_5;
  sConfig.SingleDiff = ADC_SINGLE_ENDED;
  sConfig.OffsetNumber = ADC_OFFSET_NONE;
  sConfig.Offset = 0;
  if (HAL_ADC_ConfigChannel(&hadc5, &sConfig) != HAL_OK)
  {
    Error_Handler();
  }

  /** Configure Regular Channel
  */
  sConfig.Channel = ADC_CHANNEL_7;
  sConfig.Rank = ADC_REGULAR_RANK_2;
  if (HAL_ADC_ConfigChannel(&hadc5, &sConfig) != HAL_OK)
  {
    Error_Handler();
  }

  /** Configure Regular Channel
  */
  sConfig.Channel = ADC_CHANNEL_8;
  sConfig.Rank = ADC_REGULAR_RANK_3;
  if (HAL_ADC_ConfigChannel(&hadc5, &sConfig) != HAL_OK)
  {
    Error_Handler();
  }

}

static void MX_FDCAN1_Init(void)
{

  hfdcan1.Instance = FDCAN1;
  hfdcan1.Init.ClockDivider = FDCAN_CLOCK_DIV1;
  hfdcan1.Init.FrameFormat = FDCAN_FRAME_FD_BRS;
  hfdcan1.Init.Mode = FDCAN_MODE_NORMAL;
  hfdcan1.Init.AutoRetransmission = ENABLE;
  hfdcan1.Init.TransmitPause = ENABLE;
  hfdcan1.Init.ProtocolException = DISABLE;
  hfdcan1.Init.NominalPrescaler = 17;
  hfdcan1.Init.NominalSyncJumpWidth = 4;
  hfdcan1.Init.NominalTimeSeg1 = 13;
  hfdcan1.Init.NominalTimeSeg2 = 6;
  hfdcan1.Init.DataPrescaler = 6;
  hfdcan1.Init.DataSyncJumpWidth = 4;
  hfdcan1.Init.DataTimeSeg1 = 11;
  hfdcan1.Init.DataTimeSeg2 = 5;
  hfdcan1.Init.StdFiltersNbr = 0;
  hfdcan1.Init.ExtFiltersNbr = 0;
  hfdcan1.Init.TxFifoQueueMode = FDCAN_TX_FIFO_OPERATION;
  if (HAL_FDCAN_Init(&hfdcan1) != HAL_OK)
  {
    Error_Handler();
  }

}

static void MX_I2C1_Init(void)
{

  hi2c1.Instance = I2C1;
  hi2c1.Init.Timing = 0x00802172;
  hi2c1.Init.OwnAddress1 = 2;
  hi2c1.Init.AddressingMode = I2C_ADDRESSINGMODE_7BIT;
  hi2c1.Init.DualAddressMode = I2C_DUALADDRESS_DISABLE;
  hi2c1.Init.OwnAddress2 = 0;
  hi2c1.Init.OwnAddress2Masks = I2C_OA2_NOMASK;
  hi2c1.Init.GeneralCallMode = I2C_GENERALCALL_DISABLE;
  hi2c1.Init.NoStretchMode = I2C_NOSTRETCH_DISABLE;
  if (HAL_I2C_Init(&hi2c1) != HAL_OK)
  {
    Error_Handler();
  }

  /** Configure Analogue filter
  */
  if (HAL_I2CEx_ConfigAnalogFilter(&hi2c1, I2C_ANALOGFILTER_ENABLE) != HAL_OK)
  {
    Error_Handler();
  }

  /** Configure Digital filter
  */
  if (HAL_I2CEx_ConfigDigitalFilter(&hi2c1, 0) != HAL_OK)
  {
    Error_Handler();
  }

  /** I2C Fast mode Plus enable
  */
  HAL_I2CEx_EnableFastModePlus(I2C_FASTMODEPLUS_I2C1);

}

static void MX_TIM1_Init(void)
{

  TIM_ClockConfigTypeDef sClockSourceConfig = {0};
  TIM_MasterConfigTypeDef sMasterConfig = {0};
  TIM_OC_InitTypeDef sConfigOC = {0};
  TIM_BreakDeadTimeConfigTypeDef sBreakDeadTimeConfig = {0};

  htim1.Instance = TIM1;
  htim1.Init.Prescaler = 0;
  htim1.Init.CounterMode = TIM_COUNTERMODE_UP;
  htim1.Init.Period = 1600;
  htim1.Init.ClockDivision = TIM_CLOCKDIVISION_DIV1;
  htim1.Init.RepetitionCounter = 0;
  htim1.Init.AutoReloadPreload = TIM_AUTORELOAD_PRELOAD_DISABLE;
  if (HAL_TIM_Base_Init(&htim1) != HAL_OK)
  {
    Error_Handler();
  }
  sClockSourceConfig.ClockSource = TIM_CLOCKSOURCE_INTERNAL;
  if (HAL_TIM_ConfigClockSource(&htim1, &sClockSourceConfig) != HAL_OK)
  {
    Error_Handler();
  }
  if (HAL_TIM_PWM_Init(&htim1) != HAL_OK)
  {
    Error_Handler();
  }
  sMasterConfig.MasterOutputTrigger = TIM_TRGO_RESET;
  sMasterConfig.MasterOutputTrigger2 = TIM_TRGO2_RESET;
  sMasterConfig.MasterSlaveMode = TIM_MASTERSLAVEMODE_DISABLE;
  if (HAL_TIMEx_MasterConfigSynchronization(&htim1, &sMasterConfig) != HAL_OK)
  {
    Error_Handler();
  }
  sConfigOC.OCMode = TIM_OCMODE_PWM1;
  sConfigOC.Pulse = 0;
  sConfigOC.OCPolarity = TIM_OCPOLARITY_HIGH;
  sConfigOC.OCNPolarity = TIM_OCNPOLARITY_HIGH;
  sConfigOC.OCFastMode = TIM_OCFAST_ENABLE;
  sConfigOC.OCIdleState = TIM_OCIDLESTATE_RESET;
  sConfigOC.OCNIdleState = TIM_OCNIDLESTATE_RESET;
  if (HAL_TIM_PWM_ConfigChannel(&htim1, &sConfigOC, TIM_CHANNEL_1) != HAL_OK)
  {
    Error_Handler();
  }
  if (HAL_TIM_PWM_ConfigChannel(&htim1, &sConfigOC, TIM_CHANNEL_2) != HAL_OK)
  {
    Error_Handler();
  }
  if (HAL_TIM_PWM_ConfigChannel(&htim1, &sConfigOC, TIM_CHANNEL_3) != HAL_OK)
  {
    Error_Handler();
  }
  sBreakDeadTimeConfig.OffStateRunMode = TIM_OSSR_DISABLE;
  sBreakDeadTimeConfig.OffStateIDLEMode = TIM_OSSI_DISABLE;
  sBreakDeadTimeConfig.LockLevel = TIM_LOCKLEVEL_OFF;
  sBreakDeadTimeConfig.DeadTime = 0;
  sBreakDeadTimeConfig.BreakState = TIM_BREAK_DISABLE;
  sBreakDeadTimeConfig.BreakPolarity = TIM_BREAKPOLARITY_HIGH;
  sBreakDeadTimeConfig.BreakFilter = 0;
  sBreakDeadTimeConfig.BreakAFMode = TIM_BREAK_AFMODE_INPUT;
  sBreakDeadTimeConfig.Break2State = TIM_BREAK2_DISABLE;
  sBreakDeadTimeConfig.Break2Polarity = TIM_BREAK2POLARITY_HIGH;
  sBreakDeadTimeConfig.Break2Filter = 0;
  sBreakDeadTimeConfig.Break2AFMode = TIM_BREAK_AFMODE_INPUT;
  sBreakDeadTimeConfig.AutomaticOutput = TIM_AUTOMATICOUTPUT_DISABLE;
  if (HAL_TIMEx_ConfigBreakDeadTime(&htim1, &sBreakDeadTimeConfig) != HAL_OK)
  {
    Error_Handler();
  }
  HAL_TIM_MspPostInit(&htim1);

}

static void MX_TIM2_Init(void)
{

  TIM_ClockConfigTypeDef sClockSourceConfig = {0};
  TIM_MasterConfigTypeDef sMasterConfig = {0};

  htim2.Instance = TIM2;
  htim2.Init.Prescaler = 16999;
  htim2.Init.CounterMode = TIM_COUNTERMODE_UP;
  htim2.Init.Period = 4294967295;
  htim2.Init.ClockDivision = TIM_CLOCKDIVISION_DIV1;
  htim2.Init.AutoReloadPreload = TIM_AUTORELOAD_PRELOAD_DISABLE;
  if (HAL_TIM_Base_Init(&htim2) != HAL_OK)
  {
    Error_Handler();
  }
  sClockSourceConfig.ClockSource = TIM_CLOCKSOURCE_INTERNAL;
  if (HAL_TIM_ConfigClockSource(&htim2, &sClockSourceConfig) != HAL_OK)
  {
    Error_Handler();
  }
  sMasterConfig.MasterOutputTrigger = TIM_TRGO_RESET;
  sMasterConfig.MasterSlaveMode = TIM_MASTERSLAVEMODE_DISABLE;
  if (HAL_TIMEx_MasterConfigSynchronization(&htim2, &sMasterConfig) != HAL_OK)
  {
    Error_Handler();
  }

}

static void MX_TIM3_Init(void)
{

  TIM_ClockConfigTypeDef sClockSourceConfig = {0};
  TIM_MasterConfigTypeDef sMasterConfig = {0};
  TIM_OC_InitTypeDef sConfigOC = {0};

  htim3.Instance = TIM3;
  htim3.Init.Prescaler = 0;
  htim3.Init.CounterMode = TIM_COUNTERMODE_UP;
  htim3.Init.Period = 100;
  htim3.Init.ClockDivision = TIM_CLOCKDIVISION_DIV1;
  htim3.Init.AutoReloadPreload = TIM_AUTORELOAD_PRELOAD_DISABLE;
  if (HAL_TIM_Base_Init(&htim3) != HAL_OK)
  {
    Error_Handler();
  }
  sClockSourceConfig.ClockSource = TIM_CLOCKSOURCE_INTERNAL;
  if (HAL_TIM_ConfigClockSource(&htim3, &sClockSourceConfig) != HAL_OK)
  {
    Error_Handler();
  }
  if (HAL_TIM_PWM_Init(&htim3) != HAL_OK)
  {
    Error_Handler();
  }
  sMasterConfig.MasterOutputTrigger = TIM_TRGO_RESET;
  sMasterConfig.MasterSlaveMode = TIM_MASTERSLAVEMODE_DISABLE;
  if (HAL_TIMEx_MasterConfigSynchronization(&htim3, &sMasterConfig) != HAL_OK)
  {
    Error_Handler();
  }
  sConfigOC.OCMode = TIM_OCMODE_PWM1;
  sConfigOC.Pulse = 50;
  sConfigOC.OCPolarity = TIM_OCPOLARITY_LOW;
  sConfigOC.OCFastMode = TIM_OCFAST_DISABLE;
  if (HAL_TIM_PWM_ConfigChannel(&htim3, &sConfigOC, TIM_CHANNEL_1) != HAL_OK)
  {
    Error_Handler();
  }
  if (HAL_TIM_PWM_ConfigChannel(&htim3, &sConfigOC, TIM_CHANNEL_2) != HAL_OK)
  {
    Error_Handler();
  }
  sConfigOC.Pulse = 0;
  if (HAL_TIM_PWM_ConfigChannel(&htim3, &sConfigOC, TIM_CHANNEL_3) != HAL_OK)
  {
    Error_Handler();
  }
  HAL_TIM_MspPostInit(&htim3);

}

static void MX_TIM6_Init(void)
{

  TIM_MasterConfigTypeDef sMasterConfig = {0};

  htim6.Instance = TIM6;
  htim6.Init.Prescaler = 168;
  htim6.Init.CounterMode = TIM_COUNTERMODE_UP;
  htim6.Init.Period = 100;
  htim6.Init.AutoReloadPreload = TIM_AUTORELOAD_PRELOAD_DISABLE;
  if (HAL_TIM_Base_Init(&htim6) != HAL_OK)
  {
    Error_Handler();
  }
  sMasterConfig.MasterOutputTrigger = TIM_TRGO_UPDATE;
  sMasterConfig.MasterSlaveMode = TIM_MASTERSLAVEMODE_DISABLE;
  if (HAL_TIMEx_MasterConfigSynchronization(&htim6, &sMasterConfig) != HAL_OK)
  {
    Error_Handler();
  }

}

static void MX_TIM8_Init(void)
{

  TIM_ClockConfigTypeDef sClockSourceConfig = {0};
  TIM_MasterConfigTypeDef sMasterConfig = {0};
  TIM_OC_InitTypeDef sConfigOC = {0};
  TIM_BreakDeadTimeConfigTypeDef sBreakDeadTimeConfig = {0};

  htim8.Instance = TIM8;
  htim8.Init.Prescaler = 0;
  htim8.Init.CounterMode = TIM_COUNTERMODE_UP;
  htim8.Init.Period = 1600;
  htim8.Init.ClockDivision = TIM_CLOCKDIVISION_DIV1;
  htim8.Init.RepetitionCounter = 0;
  htim8.Init.AutoReloadPreload = TIM_AUTORELOAD_PRELOAD_DISABLE;
  if (HAL_TIM_Base_Init(&htim8) != HAL_OK)
  {
    Error_Handler();
  }
  sClockSourceConfig.ClockSource = TIM_CLOCKSOURCE_INTERNAL;
  if (HAL_TIM_ConfigClockSource(&htim8, &sClockSourceConfig) != HAL_OK)
  {
    Error_Handler();
  }
  if (HAL_TIM_PWM_Init(&htim8) != HAL_OK)
  {
    Error_Handler();
  }
  sMasterConfig.MasterOutputTrigger = TIM_TRGO_RESET;
  sMasterConfig.MasterOutputTrigger2 = TIM_TRGO2_RESET;
  sMasterConfig.MasterSlaveMode = TIM_MASTERSLAVEMODE_DISABLE;
  if (HAL_TIMEx_MasterConfigSynchronization(&htim8, &sMasterConfig) != HAL_OK)
  {
    Error_Handler();
  }
  sConfigOC.OCMode = TIM_OCMODE_PWM1;
  sConfigOC.Pulse = 0;
  sConfigOC.OCPolarity = TIM_OCPOLARITY_HIGH;
  sConfigOC.OCNPolarity = TIM_OCNPOLARITY_HIGH;
  sConfigOC.OCFastMode = TIM_OCFAST_DISABLE;
  sConfigOC.OCIdleState = TIM_OCIDLESTATE_RESET;
  sConfigOC.OCNIdleState = TIM_OCNIDLESTATE_RESET;
  if (HAL_TIM_PWM_ConfigChannel(&htim8, &sConfigOC, TIM_CHANNEL_1) != HAL_OK)
  {
    Error_Handler();
  }
  if (HAL_TIM_PWM_ConfigChannel(&htim8, &sConfigOC, TIM_CHANNEL_2) != HAL_OK)
  {
    Error_Handler();
  }
  if (HAL_TIM_PWM_ConfigChannel(&htim8, &sConfigOC, TIM_CHANNEL_3) != HAL_OK)
  {
    Error_Handler();
  }
  sBreakDeadTimeConfig.OffStateRunMode = TIM_OSSR_DISABLE;
  sBreakDeadTimeConfig.OffStateIDLEMode = TIM_OSSI_DISABLE;
  sBreakDeadTimeConfig.LockLevel = TIM_LOCKLEVEL_OFF;
  sBreakDeadTimeConfig.DeadTime = 0;
  sBreakDeadTimeConfig.BreakState = TIM_BREAK_DISABLE;
  sBreakDeadTimeConfig.BreakPolarity = TIM_BREAKPOLARITY_HIGH;
  sBreakDeadTimeConfig.BreakFilter = 0;
  sBreakDeadTimeConfig.BreakAFMode = TIM_BREAK_AFMODE_INPUT;
  sBreakDeadTimeConfig.Break2State = TIM_BREAK2_DISABLE;
  sBreakDeadTimeConfig.Break2Polarity = TIM_BREAK2POLARITY_HIGH;
  sBreakDeadTimeConfig.Break2Filter = 0;
  sBreakDeadTimeConfig.Break2AFMode = TIM_BREAK_AFMODE_INPUT;
  sBreakDeadTimeConfig.AutomaticOutput = TIM_AUTOMATICOUTPUT_DISABLE;
  if (HAL_TIMEx_ConfigBreakDeadTime(&htim8, &sBreakDeadTimeConfig) != HAL_OK)
  {
    Error_Handler();
  }
  HAL_TIM_MspPostInit(&htim8);

}

static void MX_TIM20_Init(void)
{

  TIM_ClockConfigTypeDef sClockSourceConfig = {0};
  TIM_MasterConfigTypeDef sMasterConfig = {0};
  TIM_OC_InitTypeDef sConfigOC = {0};
  TIM_BreakDeadTimeConfigTypeDef sBreakDeadTimeConfig = {0};

  htim20.Instance = TIM20;
  htim20.Init.Prescaler = 0;
  htim20.Init.CounterMode = TIM_COUNTERMODE_UP;
  htim20.Init.Period = 1600;
  htim20.Init.ClockDivision = TIM_CLOCKDIVISION_DIV1;
  htim20.Init.RepetitionCounter = 0;
  htim20.Init.AutoReloadPreload = TIM_AUTORELOAD_PRELOAD_DISABLE;
  if (HAL_TIM_Base_Init(&htim20) != HAL_OK)
  {
    Error_Handler();
  }
  sClockSourceConfig.ClockSource = TIM_CLOCKSOURCE_INTERNAL;
  if (HAL_TIM_ConfigClockSource(&htim20, &sClockSourceConfig) != HAL_OK)
  {
    Error_Handler();
  }
  if (HAL_TIM_PWM_Init(&htim20) != HAL_OK)
  {
    Error_Handler();
  }
  sMasterConfig.MasterOutputTrigger = TIM_TRGO_RESET;
  sMasterConfig.MasterOutputTrigger2 = TIM_TRGO2_RESET;
  sMasterConfig.MasterSlaveMode = TIM_MASTERSLAVEMODE_DISABLE;
  if (HAL_TIMEx_MasterConfigSynchronization(&htim20, &sMasterConfig) != HAL_OK)
  {
    Error_Handler();
  }
  sConfigOC.OCMode = TIM_OCMODE_PWM1;
  sConfigOC.Pulse = 0;
  sConfigOC.OCPolarity = TIM_OCPOLARITY_HIGH;
  sConfigOC.OCNPolarity = TIM_OCNPOLARITY_HIGH;
  sConfigOC.OCFastMode = TIM_OCFAST_DISABLE;
  sConfigOC.OCIdleState = TIM_OCIDLESTATE_RESET;
  sConfigOC.OCNIdleState = TIM_OCNIDLESTATE_RESET;
  if (HAL_TIM_PWM_ConfigChannel(&htim20, &sConfigOC, TIM_CHANNEL_1) != HAL_OK)
  {
    Error_Handler();
  }
  if (HAL_TIM_PWM_ConfigChannel(&htim20, &sConfigOC, TIM_CHANNEL_2) != HAL_OK)
  {
    Error_Handler();
  }
  if (HAL_TIM_PWM_ConfigChannel(&htim20, &sConfigOC, TIM_CHANNEL_3) != HAL_OK)
  {
    Error_Handler();
  }
  sBreakDeadTimeConfig.OffStateRunMode = TIM_OSSR_DISABLE;
  sBreakDeadTimeConfig.OffStateIDLEMode = TIM_OSSI_DISABLE;
  sBreakDeadTimeConfig.LockLevel = TIM_LOCKLEVEL_OFF;
  sBreakDeadTimeConfig.DeadTime = 0;
  sBreakDeadTimeConfig.BreakState = TIM_BREAK_DISABLE;
  sBreakDeadTimeConfig.BreakPolarity = TIM_BREAKPOLARITY_HIGH;
  sBreakDeadTimeConfig.BreakFilter = 0;
  sBreakDeadTimeConfig.BreakAFMode = TIM_BREAK_AFMODE_INPUT;
  sBreakDeadTimeConfig.Break2State = TIM_BREAK2_DISABLE;
  sBreakDeadTimeConfig.Break2Polarity = TIM_BREAK2POLARITY_HIGH;
  sBreakDeadTimeConfig.Break2Filter = 0;
  sBreakDeadTimeConfig.Break2AFMode = TIM_BREAK_AFMODE_INPUT;
  sBreakDeadTimeConfig.AutomaticOutput = TIM_AUTOMATICOUTPUT_DISABLE;
  if (HAL_TIMEx_ConfigBreakDeadTime(&htim20, &sBreakDeadTimeConfig) != HAL_OK)
  {
    Error_Handler();
  }
  HAL_TIM_MspPostInit(&htim20);

}

static void MX_UART4_Init(void)
{

  huart4.Instance = UART4;
  huart4.Init.BaudRate = 115200;
  huart4.Init.WordLength = UART_WORDLENGTH_8B;
  huart4.Init.StopBits = UART_STOPBITS_1;
  huart4.Init.Parity = UART_PARITY_NONE;
  huart4.Init.Mode = UART_MODE_TX_RX;
  huart4.Init.HwFlowCtl = UART_HWCONTROL_NONE;
  huart4.Init.OverSampling = UART_OVERSAMPLING_16;
  huart4.Init.OneBitSampling = UART_ONE_BIT_SAMPLE_DISABLE;
  huart4.Init.ClockPrescaler = UART_PRESCALER_DIV1;
  huart4.AdvancedInit.AdvFeatureInit = UART_ADVFEATURE_NO_INIT;
  if (HAL_UART_Init(&huart4) != HAL_OK)
  {
    Error_Handler();
  }
  if (HAL_UARTEx_SetTxFifoThreshold(&huart4, UART_TXFIFO_THRESHOLD_1_8) != HAL_OK)
  {
    Error_Handler();
  }
  if (HAL_UARTEx_SetRxFifoThreshold(&huart4, UART_RXFIFO_THRESHOLD_1_8) != HAL_OK)
  {
    Error_Handler();
  }
  if (HAL_UARTEx_DisableFifoMode(&huart4) != HAL_OK)
  {
    Error_Handler();
  }

}

static void MX_USART1_UART_Init(void)
{

  huart1.Instance = USART1;
  huart1.Init.BaudRate = 115200;
  huart1.Init.WordLength = UART_WORDLENGTH_8B;
  huart1.Init.StopBits = UART_STOPBITS_1;
  huart1.Init.Parity = UART_PARITY_NONE;
  huart1.Init.Mode = UART_MODE_TX_RX;
  huart1.Init.HwFlowCtl = UART_HWCONTROL_NONE;
  huart1.Init.OverSampling = UART_OVERSAMPLING_16;
  huart1.Init.OneBitSampling = UART_ONE_BIT_SAMPLE_DISABLE;
  huart1.Init.ClockPrescaler = UART_PRESCALER_DIV1;
  huart1.AdvancedInit.AdvFeatureInit = UART_ADVFEATURE_NO_INIT;
  if (HAL_UART_Init(&huart1) != HAL_OK)
  {
    Error_Handler();
  }
  if (HAL_UARTEx_SetTxFifoThreshold(&huart1, UART_TXFIFO_THRESHOLD_1_8) != HAL_OK)
  {
    Error_Handler();
  }
  if (HAL_UARTEx_SetRxFifoThreshold(&huart1, UART_RXFIFO_THRESHOLD_1_8) != HAL_OK)
  {
    Error_Handler();
  }
  if (HAL_UARTEx_DisableFifoMode(&huart1) != HAL_OK)
  {
    Error_Handler();
  }

}

static void MX_USART2_UART_Init(void)
{

  huart2.Instance = USART2;
  huart2.Init.BaudRate = 115200;
  huart2.Init.WordLength = UART_WORDLENGTH_8B;
  huart2.Init.StopBits = UART_STOPBITS_1;
  huart2.Init.Parity = UART_PARITY_NONE;
  huart2.Init.Mode = UART_MODE_TX_RX;
  huart2.Init.HwFlowCtl = UART_HWCONTROL_NONE;
  huart2.Init.OverSampling = UART_OVERSAMPLING_16;
  huart2.Init.OneBitSampling = UART_ONE_BIT_SAMPLE_DISABLE;
  huart2.Init.ClockPrescaler = UART_PRESCALER_DIV1;
  huart2.AdvancedInit.AdvFeatureInit = UART_ADVFEATURE_NO_INIT;
  if (HAL_UART_Init(&huart2) != HAL_OK)
  {
    Error_Handler();
  }
  if (HAL_UARTEx_SetTxFifoThreshold(&huart2, UART_TXFIFO_THRESHOLD_1_8) != HAL_OK)
  {
    Error_Handler();
  }
  if (HAL_UARTEx_SetRxFifoThreshold(&huart2, UART_RXFIFO_THRESHOLD_1_8) != HAL_OK)
  {
    Error_Handler();
  }
  if (HAL_UARTEx_DisableFifoMode(&huart2) != HAL_OK)
  {
    Error_Handler();
  }

}

static void MX_USART3_UART_Init(void)
{

  huart3.Instance = USART3;
  huart3.Init.BaudRate = 115200;
  huart3.Init.WordLength = UART_WORDLENGTH_8B;
  huart3.Init.StopBits = UART_STOPBITS_1;
  huart3.Init.Parity = UART_PARITY_NONE;
  huart3.Init.Mode = UART_MODE_TX_RX;
  huart3.Init.HwFlowCtl = UART_HWCONTROL_NONE;
  huart3.Init.OverSampling = UART_OVERSAMPLING_16;
  huart3.Init.OneBitSampling = UART_ONE_BIT_SAMPLE_DISABLE;
  huart3.Init.ClockPrescaler = UART_PRESCALER_DIV1;
  huart3.AdvancedInit.AdvFeatureInit = UART_ADVFEATURE_NO_INIT;
  if (HAL_UART_Init(&huart3) != HAL_OK)
  {
    Error_Handler();
  }
  if (HAL_UARTEx_SetTxFifoThreshold(&huart3, UART_TXFIFO_THRESHOLD_1_8) != HAL_OK)
  {
    Error_Handler();
  }
  if (HAL_UARTEx_SetRxFifoThreshold(&huart3, UART_RXFIFO_THRESHOLD_1_8) != HAL_OK)
  {
    Error_Handler();
  }
  if (HAL_UARTEx_DisableFifoMode(&huart3) != HAL_OK)
  {
    Error_Handler();
  }

}

static void MX_DMA_Init(void)
{

  /* DMA controller clock enable */
  __HAL_RCC_DMAMUX1_CLK_ENABLE();
  __HAL_RCC_DMA1_CLK_ENABLE();

  /* DMA interrupt init */
  /* DMA1_Channel1_IRQn interrupt configuration */
  HAL_NVIC_SetPriority(DMA1_Channel1_IRQn, 1, 0);
  HAL_NVIC_EnableIRQ(DMA1_Channel1_IRQn);
  /* DMA1_Channel2_IRQn interrupt configuration */
  HAL_NVIC_SetPriority(DMA1_Channel2_IRQn, 3, 0);
  HAL_NVIC_EnableIRQ(DMA1_Channel2_IRQn);
  /* DMA1_Channel3_IRQn interrupt configuration */
  HAL_NVIC_SetPriority(DMA1_Channel3_IRQn, 0, 0);
  HAL_NVIC_EnableIRQ(DMA1_Channel3_IRQn);
  /* DMA1_Channel4_IRQn interrupt configuration */
  HAL_NVIC_SetPriority(DMA1_Channel4_IRQn, 0, 0);
  HAL_NVIC_EnableIRQ(DMA1_Channel4_IRQn);
  /* DMA1_Channel5_IRQn interrupt configuration */
  HAL_NVIC_SetPriority(DMA1_Channel5_IRQn, 0, 0);
  HAL_NVIC_EnableIRQ(DMA1_Channel5_IRQn);

}

static void MX_GPIO_Init(void)
{
  GPIO_InitTypeDef GPIO_InitStruct = {0};

  /* GPIO Ports Clock Enable */
  __HAL_RCC_GPIOE_CLK_ENABLE();
  __HAL_RCC_GPIOB_CLK_ENABLE();
  __HAL_RCC_GPIOD_CLK_ENABLE();
  __HAL_RCC_GPIOA_CLK_ENABLE();
  __HAL_RCC_GPIOC_CLK_ENABLE();
  __HAL_RCC_GPIOF_CLK_ENABLE();

  /*Configure GPIO pin : BOOT0_SENSE_Pin */
  GPIO_InitStruct.Pin = BOOT0_SENSE_Pin;
  GPIO_InitStruct.Mode = GPIO_MODE_INPUT;
  GPIO_InitStruct.Pull = GPIO_NOPULL;
  HAL_GPIO_Init(BOOT0_SENSE_GPIO_Port, &GPIO_InitStruct);

  /*Configure GPIO pins : ADDR_0_Pin ADDR_4_Pin ADDR_3_Pin ADDR_5_Pin
                           ADDR_2_Pin ADDR_1_Pin */
  GPIO_InitStruct.Pin = ADDR_0_Pin|ADDR_4_Pin|ADDR_3_Pin|ADDR_5_Pin
                          |ADDR_2_Pin|ADDR_1_Pin;
  GPIO_InitStruct.Mode = GPIO_MODE_INPUT;
  GPIO_InitStruct.Pull = GPIO_PULLUP;
  HAL_GPIO_Init(GPIOD, &GPIO_InitStruct);

}

/* USER CODE BEGIN 4 */

//void HAL_ADC_ConvCpltCallback(ADC_HandleTypeDef *hadc) {
//	if (hadc == &hadc3) {
//		EA_SENSE_1 = HAL_ADC_GetValue(hadc);
//		coil_current_1 = (float) EA_SENSE_1 / 65535.0f * 3.0f / 0.12f;
//		if (current_setpoint > 3 || coil_current_1 > 3.2) {
//			TIM1->CCR1 = 0;
//			current_setpoint = 0;
//			return;
//		}
//		pid_error = current_setpoint - coil_current_1;
//		pid_error_integral += pid_error;
//		// clamp integral to +- 10
//		if (pid_error_integral > PID_I_CLAMP) {
//			pid_error_integral = PID_I_CLAMP;
//		} else if (pid_error_integral < -PID_I_CLAMP) {
//			pid_error_integral = -PID_I_CLAMP;
//		}
//		pid_pwm_change = Kp * pid_error + Ki * pid_error_integral;
//		pid_pwm_output += pid_pwm_change;
//		if (pid_pwm_output >= 0.98f) {
//			pid_pwm_output = 0.98f;
//		} else if (pid_pwm_output < 0.0f) {
//			pid_pwm_output = 0.0f;
//		}
//		coil_pwm_ccr_1 = pid_pwm_output * 1600.0f;
//		__HAL_TIM_SET_COMPARE(&htim1, TIM_CHANNEL_1, coil_pwm_ccr_1);
//	}
//}

/* USER CODE END 4 */

void Error_Handler(void)
{
	__disable_irq();
	while (1) {
	}
}
